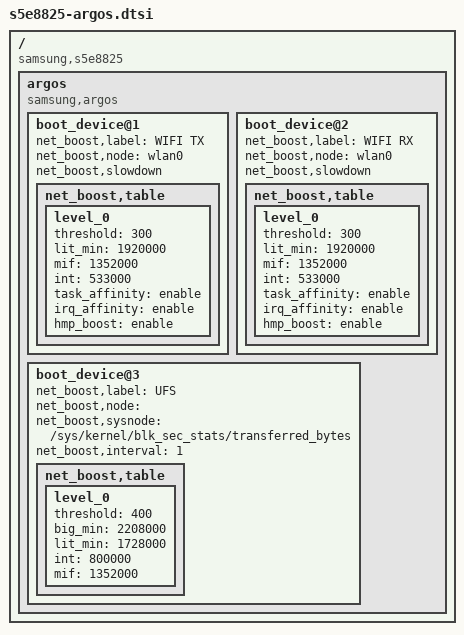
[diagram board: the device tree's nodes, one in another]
/*
 * SAMSUNG S5E8825 Argos Device Tree Source
 *
 * Copyright (c) 2021 Samsung Electronics Co., Ltd.
 *		http://www.samsung.com
 *
 * This program is free software; you can redistribute it and/or modify
 * it under the terms of the GNU General Public License version 2 as
 * published by the Free Software Foundation.
 */

/ {
	compatible = "samsung,s5e8825";

	fragment@common {
		target-path = "/";
		__overlay__ {
			#address-cells = <2>;
			#size-cells = <1>;

			argos {
				compatible = "samsung,argos";
				#address-cells = <1>;
				/*  The device number should be assigned for each device, e.g. "boot_device@1" and "boot_device@2".
				 * Duplicated number is not allowed. Please refer the below example.
				 */

				/* net_bootst,interval : device throughput scan interval
				 *          0 - 1000 ms(default), 1 - 500 ms, 2 - 250 ms
				 */

				/* net_bootst,table Format
				 * threshold : throughput threshold(Mbps)
				 * big_min : Big Core's minimum frequency lock. 0 means not set,
				 * big_max : Big Core's maximum frequency lock. 0 means not set,
				 * mid_min : Middle Core's minimum frequency lock. 0 means not set,
				 * mid_max : Middle Core's maximum frequency lock. 0 means not set,
				 * lit_min : Little Core's minimum frequency lock. 0 means not set,
				 * lit_max : Little Core's maximum frequency lock. 0 means not set,
				 * mif : MIF frequency lock. 0 means not set,
				 * int : INT frequency lock. 0 means not set,
				 * task_affinity : "enable" - Set task affinity lock.
				 *	           "disable" - Not set or unlock,
				 *		   Task affinity should be predefined driver's code.
				 * irq_affinity : "enable" - Set irq affinity lock.
				 *                "disable" - Not set or unlock,
				 *		  IRQ affinity should be predefined driver's code.
				 * hmp_boot : "enable" - Increase hmp boosting count
				 *            "disable" - Decrease hmp boosting count
				 */

				boot_device@1 {
					net_boost,label="WIFI TX";
					net_boost,node="wlan0";
					net_boost,slowdown;
					net_boost,table {
						level_0 {
							threshold = <300>;
							lit_min = <1920000>;
							mif = <1352000>;
							int = <533000>;
							task_affinity = "enable";
							irq_affinity = "enable";
							hmp_boost = "enable";
						};
					};
				};

				boot_device@2 {
					net_boost,label="WIFI RX";
					net_boost,node="wlan0";
					net_boost,slowdown;
					net_boost,table {
						level_0 {
							threshold = <300>;
							lit_min = <1920000>;
							mif = <1352000>;
							int = <533000>;
							task_affinity = "enable";
							irq_affinity = "enable";
							hmp_boost = "enable";
						};
					};
				};

				boot_device@3 {
					net_boost,label="UFS";
					net_boost,node="";
					net_boost,sysnode="/sys/kernel/blk_sec_stats/transferred_bytes";
					net_boost,interval= <1>;
					net_boost,table {
						level_0 {
							threshold = <400>; /* 50 MB/0.5s */
							big_min = <2208000>;
							lit_min = <1728000>;
							int = <800000>;
							mif = <1352000>;
						};

					};
				};

			};
		}; /* end of __overlay__ */
	}; /* end of fragment */
}; /* end of root */
